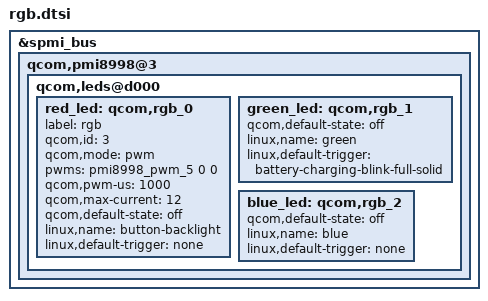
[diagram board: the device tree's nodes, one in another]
&spmi_bus {
  qcom,pmi8998@3 {
		qcom,leds@d000 {
			status = "okay";
			/delete-node/ qcom,rgb_0;
			red_led: qcom,rgb_0 {
				label = "rgb";
				qcom,id = <3>;
				qcom,mode = "pwm";
				pwms = <&pmi8998_pwm_5 0 0>;
				qcom,pwm-us = <1000>;
				qcom,max-current = <12>;
				qcom,default-state = "off";
				linux,name = "button-backlight";
				linux,default-trigger = "none";
			};
			green_led: qcom,rgb_1 {
				qcom,default-state = "off";
				linux,name = "green";
				linux,default-trigger = "battery-charging-blink-full-solid";
			};

			blue_led: qcom,rgb_2 {
				qcom,default-state = "off";
				linux,name = "blue";
				linux,default-trigger = "none";
			};
		};
	};
};
